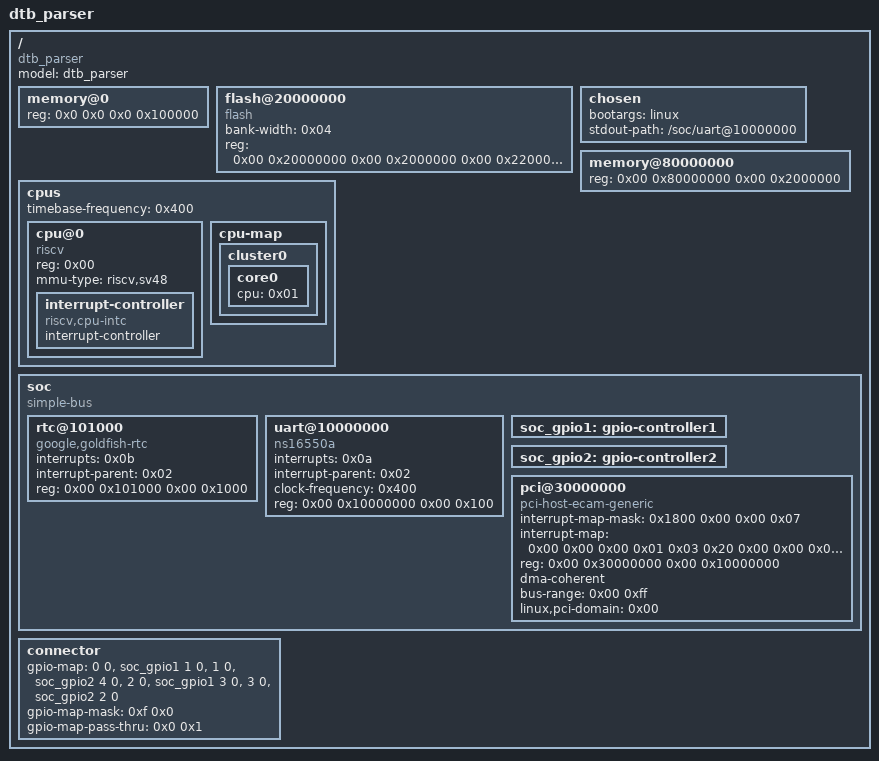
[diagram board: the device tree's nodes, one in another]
/dts-v1/;

/ {
	compatible = "dtb_parser";
	model = "dtb_parser";
	#address-cells = <0x02>;
	#size-cells = <0x02>;

	memory@0 {
		device_type = "memory";
		reg = <0x0 0x0 0x0 0x100000>;
	};

	flash@20000000 {
		bank-width = <0x04>;
		reg = <0x00 0x20000000 0x00 0x2000000 0x00 0x22000000 0x00 0x2000000>;
		compatible = "flash";
	};

	chosen {
		bootargs = "linux";
		stdout-path = "/soc/uart@10000000";
	};

	memory@80000000 {
		device_type = "memory";
		reg = <0x00 0x80000000 0x00 0x2000000>;
	};

	cpus {
		timebase-frequency = <0x400>;
		#address-cells = <0x01>;
		#size-cells = <0x00>;

		cpu@0 {
			phandle = <0x01>;
			device_type = "cpu";
			reg = <0x00>;
			status = "okay";
			compatible = "riscv";
			mmu-type = "riscv,sv48";

			interrupt-controller {
				interrupt-controller;
				compatible = "riscv,cpu-intc";
				phandle = <0x02>;
			    #address-cells = <0x1>;
				#interrupt-cells = <0x01>;
			};
		};

		cpu-map {

			cluster0 {

				core0 {
					cpu = <0x01>;
				};
			};
		};
	};

	soc {
		compatible = "simple-bus";
		ranges;
		#address-cells = <0x02>;
		#size-cells = <0x02>;

		rtc@101000 {
			interrupts = <0x0b>;
			interrupt-parent = <0x02>;
			reg = <0x00 0x101000 0x00 0x1000>;
			compatible = "google,goldfish-rtc";
		};

		uart@10000000 {
			interrupts = <0x0a>;
			interrupt-parent = <0x02>;
			clock-frequency = <0x400>;
			reg = <0x00 0x10000000 0x00 0x100>;
			compatible = "ns16550a";
		};

		soc_gpio1: gpio-controller1 {
            #gpio-cells = <2>;
        };

        soc_gpio2: gpio-controller2 {
            #gpio-cells = <2>;
        };

        pci@30000000 {
            interrupt-map-mask = <0x1800 0x00 0x00 0x07>;
            interrupt-map = <0x00 0x00 0x00 0x01 0x03 0x20 0x00 0x00 0x00 0x02 0x03 0x21 0x00 0x00 0x00 0x03 0x03 0x22 0x00 0x00 0x00 0x04 0x03 0x23 0x800 0x00 0x00 0x01 0x03 0x21 0x800 0x00 0x00 0x02 0x03 0x22 0x800 0x00 0x00 0x03 0x03 0x23 0x800 0x00 0x00 0x04 0x03 0x20 0x1000 0x00 0x00 0x01 0x03 0x22 0x1000 0x00 0x00 0x02 0x03 0x23 0x1000 0x00 0x00 0x03 0x03 0x20 0x1000 0x00 0x00 0x04 0x03 0x21 0x1800 0x00 0x00 0x01 0x03 0x23 0x1800 0x00 0x00 0x02 0x03 0x20 0x1800 0x00 0x00 0x03 0x03 0x21 0x1800 0x00 0x00 0x04 0x03 0x22>;
            ranges = <0x1000000 0x00 0x00 0x00 0x3000000 0x00 0x10000 0x2000000 0x00 0x40000000 0x00 0x40000000 0x00 0x40000000 0x3000000 0x04 0x00 0x04 0x00 0x04 0x00>;
            reg = <0x00 0x30000000 0x00 0x10000000>;
            dma-coherent;
            bus-range = <0x00 0xff>;
            linux,pci-domain = <0x00>;
            device_type = "pci";
            compatible = "pci-host-ecam-generic";
            #size-cells = <0x02>;
            #interrupt-cells = <0x01>;
            #address-cells = <0x03>;
        };
	};

	connector: connector {
	    #gpio-cells = <2>;
	    gpio-map =  <0 0 &soc_gpio1 1 0>,
	                <1 0 &soc_gpio2 4 0>,
                    <2 0 &soc_gpio1 3 0>,
                    <3 0 &soc_gpio2 2 0>;
        gpio-map-mask = <0xf 0x0>;
        gpio-map-pass-thru = <0x0 0x1>;
    };
};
